# ATSAM3X8H register map
Vendor: Atmel; Series: SAM3X; File version: 0
CPU: CM3 r2p0, selectable endian, MPU, no FPU, 4 interrupt priority bits
Registers are 32-bit, read-write, reset 0x0 unless marked. A register's access mark holds for its fields unless they carry their own. Offsets are from the block's base; [hi:lo] are bit positions; {n}, {i} and the like mark numbered series; 'fields as' and 'values as' point back to an identical list.

## TRNG — True Random Number Generator
Base 0x400BC000; register names take the prefix TRNG_
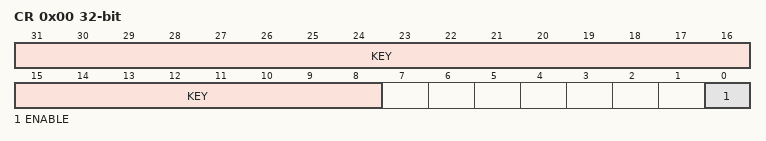
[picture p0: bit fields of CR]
0x00 CR wo reset not defined — Control Register
  [31:8] KEY — Security Key
  [0] ENABLE — Enables the TRNG to provide random values
0x10 IER wo reset not defined — Interrupt Enable Register
  [0] DATRDY — Data Ready Interrupt Enable
0x14 IDR wo reset not defined — Interrupt Disable Register
  [0] DATRDY — Data Ready Interrupt Disable
0x18 IMR ro — Interrupt Mask Register
  [0] DATRDY — Data Ready Interrupt Mask
0x1C ISR ro — Interrupt Status Register
  [0] DATRDY — Data Ready
0x50 ODATA ro — Output Data Register
  [31:0] ODATA — Output Data

## MATRIX — AHB Bus Matrix
Base 0x400E0400
{0x0+4i} MATRIX_MCFG[{i}] (i=0..5) reset not defined — Master Configuration Register
  [2:0] ULBT — Undefined Length Burst Type
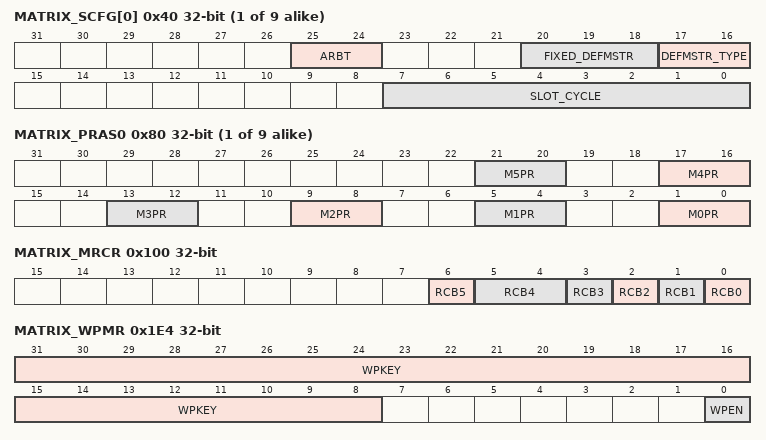
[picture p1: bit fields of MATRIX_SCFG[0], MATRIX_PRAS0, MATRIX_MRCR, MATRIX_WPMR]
{0x40+4i} MATRIX_SCFG[{i}] (i=0..8) reset not defined — Slave Configuration Register
  [25:24] ARBT — Arbitration Type
  [20:18] FIXED_DEFMSTR — Fixed Default Master
  [17:16] DEFMSTR_TYPE — Default Master Type
  [7:0] SLOT_CYCLE — Maximum Number of Allowed Cycles for a Burst
{0x80+8i} MATRIX_PRAS{i} (i=0..8) — Priority Register A for Slave {i}
  [4n+1:4n] M{n}PR (n=0..5) — Master {n} Priority
0x100 MATRIX_MRCR — Master Remap Control Register
  [6] RCB5 — Remap Command Bit for AHB Master 5
  [5:4] RCB4 — Remap Command Bit for AHB Master 4
  [n] RCB{n} (n=0..3) — Remap Command Bit for AHB Master {n}
0x114 CCFG_SYSIO — System I/O Configuration register
  [12] SYSIO12 — PC0 or ERASE Assignment
0x1E4 MATRIX_WPMR — Write Protect Mode Register
  [31:8] WPKEY — Write Protect KEY (Write-only)
  [0] WPEN — Write Protect ENable
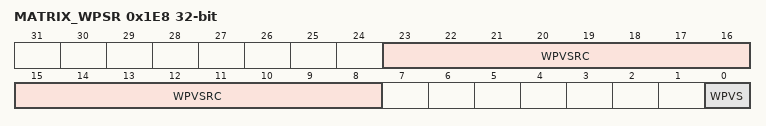
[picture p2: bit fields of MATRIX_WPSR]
0x1E8 MATRIX_WPSR ro — Write Protect Status Register
  [23:8] WPVSRC — Write Protect Violation Source
  [0] WPVS — Write Protect Violation Status

## CHIPID — Chip Identifier
Base 0x400E0940; register names take the prefix CHIPID_
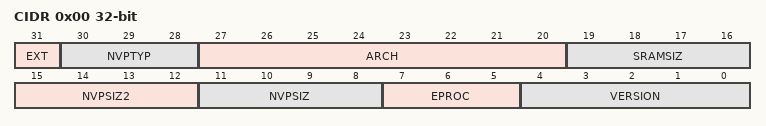
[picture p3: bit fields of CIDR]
0x00 CIDR ro reset not defined — Chip ID Register
  [31] EXT — Extension Flag
  [30:28] NVPTYP — Nonvolatile Program Memory Type
    0=ROM; 1=ROMLESS (ROMless or on-chip Flash); 2=FLASH (Embedded Flash Memory); 3=ROM_FLASH (ROM and Embedded Flash Memory- NVPSIZ is ROM size- NVPSIZ2 is Flash size); 4=SRAM (SRAM emulating ROM)
  [27:20] ARCH — Architecture Identifier
    131=SAM3AxC (100-pin version); 132=SAM3XxC (100-pin version); 133=SAM3XxE (144-pin version); 134=SAM3XxG (208/217-pin version)
  [19:16] SRAMSIZ — Internal SRAM Size
    0=48K (48 Kbytes); 1=192K (192 Kbytes); 2=2K (2 Kbytes); 3=6K (6 Kbytes); 4=24K (24 Kbytes); 5=4K (4 Kbytes); 6=80K (80 Kbytes); 7=160K (160 Kbytes); 8=8K (8 Kbytes); 9=16K (16 Kbytes); 10=32K (32 Kbytes); 11=64K (64 Kbytes); 12=128K (128 Kbytes); 13=256K (256 Kbytes); 14=96K (96 Kbytes); 15=512K (512 Kbytes)
  [15:12] NVPSIZ2 — Second Nonvolatile Program Memory Size
    0=NONE; 1=8K (8 Kbytes); 2=16K (16 Kbytes); 3=32K (32 Kbytes); 5=64K (64 Kbytes); 7=128K (128 Kbytes); 9=256K (256 Kbytes); 10=512K (512 Kbytes); 12=1024K (1024 Kbytes); 14=2048K (2048 Kbytes)
  [11:8] NVPSIZ — Nonvolatile Program Memory Size
    values as NVPSIZ2
  [7:5] EPROC — Embedded Processor
    1=ARM946ES; 2=ARM7TDMI; 3=CM3 (Cortex-M3); 4=ARM920T; 5=ARM926EJS; 6=CA5 (Cortex-A5); 7=CM4 (Cortex-M4)
  [4:0] VERSION — Version of the Device
0x04 EXID ro reset not defined — Chip ID Extension Register
  [31:0] EXID — Chip ID Extension

## EFC0 — Embedded Flash Controller 0
Base 0x400E0A00; register names take the prefix EFC0_
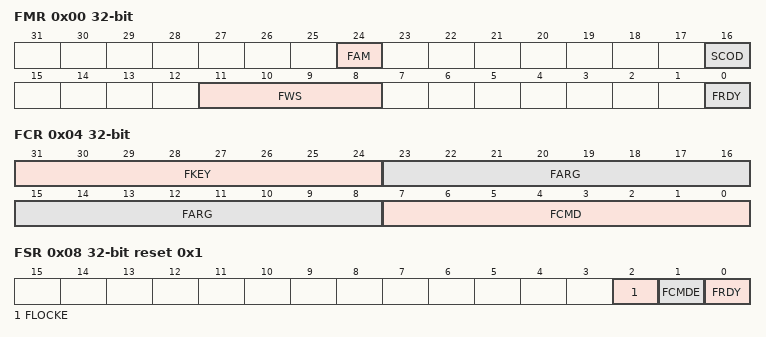
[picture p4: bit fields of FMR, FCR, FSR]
0x00 FMR — EEFC Flash Mode Register
  [24] FAM — Flash Access Mode
  [16] SCOD — Sequential Code Optimization Disable
  [11:8] FWS — Flash Wait State
  [0] FRDY — Ready Interrupt Enable
0x04 FCR wo reset not defined — EEFC Flash Command Register
  [31:24] FKEY — Flash Writing Protection Key
    90=PASSWD (The 0x5A value enables the command defined by the bits of the register. If the field is written with a different value, the write is not performed and no action is started.)
  [23:8] FARG — Flash Command Argument
  [7:0] FCMD — Flash Command
    0=GETD (Get Flash Descriptor); 1=WP (Write page); 2=WPL (Write page and lock); 3=EWP (Erase page and write page); 4=EWPL (Erase page and write page then lock); 5=EA (Erase all); 8=SLB (Set Lock Bit); 9=CLB (Clear Lock Bit); 10=GLB (Get Lock Bit); 11=SGPB (Set GPNVM Bit); 12=CGPB (Clear GPNVM Bit); 13=GGPB (Get GPNVM Bit); 14=STUI (Start Read Unique Identifier); 15=SPUI (Stop Read Unique Identifier); 16=GCALB (Get CALIB Bit)
0x08 FSR ro reset 0x1 — EEFC Flash Status Register
  [2] FLOCKE — Flash Lock Error Status
  [1] FCMDE — Flash Command Error Status
  [0] FRDY — Flash Ready Status
0x0C FRR ro — EEFC Flash Result Register
  [31:0] FVALUE — Flash Result Value

## EFC1 — Embedded Flash Controller 1
Base 0x400E0C00; register names take the prefix EFC1_
Registers as EFC0.

## RSTC — Reset Controller
Base 0x400E1A00; register names take the prefix RSTC_
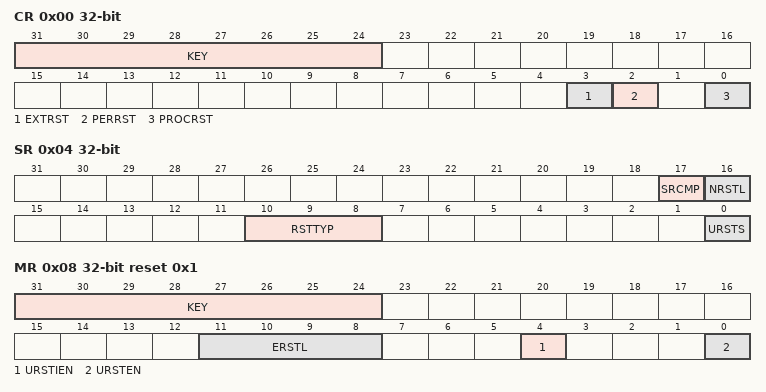
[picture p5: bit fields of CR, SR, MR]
0x00 CR wo reset not defined — Control Register
  [31:24] KEY — System Reset Key
    165=PASSWD (Writing any other value in this field aborts the write operation.)
  [3] EXTRST — External Reset
  [2] PERRST — Peripheral Reset
  [0] PROCRST — Processor Reset
0x04 SR ro — Status Register
  [17] SRCMP — Software Reset Command in Progress
  [16] NRSTL — NRST Pin Level
  [10:8] RSTTYP — Reset Type
    0=GeneralReset (First power-up Reset); 1=BackupReset (Return from Backup Mode); 2=WatchdogReset (Watchdog fault occurred); 3=SoftwareReset (Processor reset required by the software); 4=UserReset (NRST pin detected low)
  [0] URSTS — User Reset Status
0x08 MR reset 0x1 — Mode Register
  [31:24] KEY — Write Access Password
    165=PASSWD (Writing any other value in this field aborts the write operation.Always reads as 0.)
  [11:8] ERSTL — External Reset Length
  [4] URSTIEN — User Reset Interrupt Enable
  [0] URSTEN — User Reset Enable

## RTT — Real-time Timer
Base 0x400E1A30; register names take the prefix RTT_
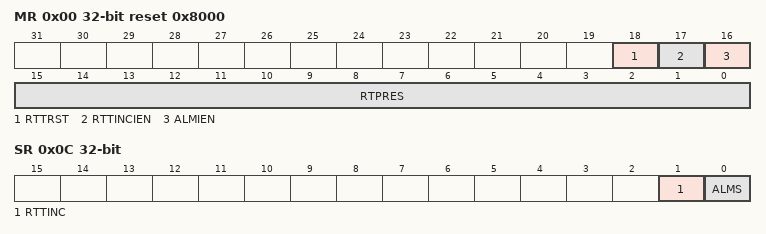
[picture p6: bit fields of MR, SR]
0x00 MR reset 0x8000 — Mode Register
  [18] RTTRST — Real-time Timer Restart
  [17] RTTINCIEN — Real-time Timer Increment Interrupt Enable
  [16] ALMIEN — Alarm Interrupt Enable
  [15:0] RTPRES — Real-time Timer Prescaler Value
0x04 AR reset 0xFFFFFFFF — Alarm Register
  [31:0] ALMV — Alarm Value
0x08 VR ro — Value Register
  [31:0] CRTV — Current Real-time Value
0x0C SR ro — Status Register
  [1] RTTINC — Real-time Timer Increment
  [0] ALMS — Real-time Alarm Status

## WDT — Watchdog Timer
Base 0x400E1A50; register names take the prefix WDT_
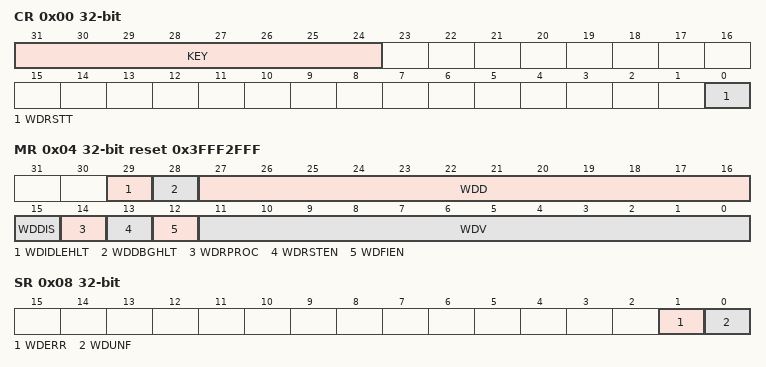
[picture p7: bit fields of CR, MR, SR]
0x00 CR wo reset not defined — Control Register
  [31:24] KEY — Password.
    165=PASSWD (Writing any other value in this field aborts the write operation.)
  [0] WDRSTT — Watchdog Restart
0x04 MR reset 0x3FFF2FFF — Mode Register
  [29] WDIDLEHLT — Watchdog Idle Halt
  [28] WDDBGHLT — Watchdog Debug Halt
  [27:16] WDD — Watchdog Delta Value
  [15] WDDIS — Watchdog Disable
  [14] WDRPROC — Watchdog Reset Processor
  [13] WDRSTEN — Watchdog Reset Enable
  [12] WDFIEN — Watchdog Fault Interrupt Enable
  [11:0] WDV — Watchdog Counter Value
0x08 SR ro — Status Register
  [1] WDERR — Watchdog Error
  [0] WDUNF — Watchdog Underflow

## GPBR — General Purpose Backup Registers
Base 0x400E1A90; register names take the prefix GPBR_
{0x0+4i} GPBR[{i}] (i=0..7) reset not defined — General Purpose Backup Register
  [31:0] GPBR_VALUE — Value of GPBR x
